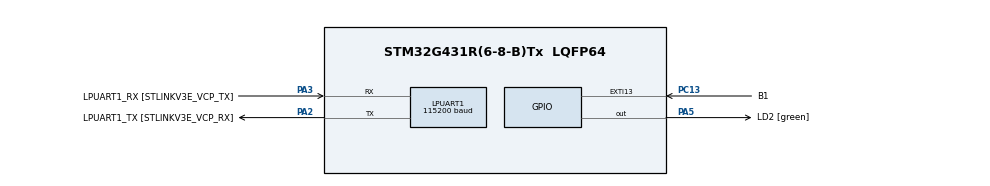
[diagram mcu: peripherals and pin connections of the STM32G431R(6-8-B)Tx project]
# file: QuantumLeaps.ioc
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LPUART1.BaudRate=115200
LPUART1.FIFOMode=UART_FIFOMODE_ENABLE
Mcu.Family=STM32G4
Mcu.Name=STM32G431R(6-8-B)Tx
Mcu.Package=LQFP64
NVIC.EXTI15_10_IRQn=true\:0\:0\:false\:false\:true\:true\:true\:false
NVIC.LPUART1_IRQn=true\:0\:0\:false\:false\:true\:true\:true\:true
NVIC.PriorityGroup=NVIC_PRIORITYGROUP_4
PA13.GPIO_Label=T_SWDIO
PA13.Signal=SYS_JTMS-SWDIO
PA14.GPIO_Label=T_SWCLK
PA14.Signal=SYS_JTCK-SWCLK
PA2.GPIO_Label=LPUART1_TX [STLINKV3E_VCP_RX]
PA2.Mode=Asynchronous
PA2.Signal=LPUART1_TX
PA3.GPIO_Label=LPUART1_RX [STLINKV3E_VCP_TX]
PA3.Mode=Asynchronous
PA3.Signal=LPUART1_RX
PA5.GPIO_Label=LD2 [green]
PA5.Signal=GPIO_Output
PB3.GPIO_Label=T_SWO
PB3.Signal=SYS_JTDO-SWO
PC13.GPIO_Label=B1
PC13.Signal=GPXTI13
PC14-OSC32_IN.GPIO_Label=RCC_OSC32_OUT
PC14-OSC32_IN.Signal=RCC_OSC32_IN
PC15-OSC32_OUT.GPIO_Label=RCC_OSC32_OUT
PC15-OSC32_OUT.Signal=RCC_OSC32_OUT
PF0-OSC_IN.GPIO_Label=RCC_OSC_IN
PF0-OSC_IN.Signal=RCC_OSC_IN
PF1-OSC_OUT.GPIO_Label=RCC_OSC_OUT
PF1-OSC_OUT.Signal=RCC_OSC_OUT
ProjectManager.HeapSize=0x200
ProjectManager.StackSize=0x400
ProjectManager.TargetToolchain=STM32CubeIDE
QuantumLeaps.qpc.7.3.4.qpcCcRTEFJjEventOoProcessor=qep
QuantumLeaps.qpc.7.3.4.qpcCcRTEFJjFramework=qf
QuantumLeaps.qpc.7.3.4.qpcCcRTEFJjRealAaTimeOoKernel=qk
QuantumLeaps.qpc.7.3.4.qpcCcRTEFJjSoftwareOotracing=qs
RCC.ADC12Freq_Value=170000000
RCC.AHBFreq_Value=170000000
RCC.APB1Freq_Value=170000000
RCC.APB1TimFreq_Value=170000000
RCC.APB2Freq_Value=170000000
RCC.APB2TimFreq_Value=170000000
RCC.CortexFreq_Value=170000000
RCC.EXTERNAL_CLOCK_VALUE=12288000
RCC.HCLKFreq_Value=170000000
RCC.HSE_VALUE=24000000
RCC.HSI48_VALUE=48000000
RCC.HSI_VALUE=16000000
RCC.LSE_VALUE=32768
RCC.PLLM=RCC_PLLM_DIV4
RCC.PLLN=85
RCC.RTCClockSelection=RCC_RTCCLKSOURCE_LSE
RCC.SYSCLKFreq_VALUE=170000000
RCC.SYSCLKSource=RCC_SYSCLKSOURCE_PLLCLK
RCC.USBFreq_Value=170000000
RCC.VCOOutputFreq_Value=340000000
VP_QuantumLeaps.qpc_VS_RTEFJjqpc_7.3.4_7.3.4.Mode=RTEFJjqpc
VP_SYS_VS_DBSignals.Mode=DisableDeadBatterySignals
board=NUCLEO-G431RB

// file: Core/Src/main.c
/* USER CODE BEGIN Header */
/**
  ******************************************************************************
  * @file           : main.c
  * @brief          : Main program body
  ******************************************************************************
  * @attention
  *
  * Copyright (c) 2024 STMicroelectronics.
  * All rights reserved.
  *
  * This software is licensed under terms that can be found in the LICENSE file
  * in the root directory of this software component.
  * If no LICENSE file comes with this software, it is provided AS-IS.
  *
  ******************************************************************************
  */
/* USER CODE END Header */
#include "main.h"

/* USER CODE BEGIN Includes */
#include "qpc.h"
#include <stdio.h>
/* USER CODE END Includes */

void SystemClock_Config(void);
static void MX_GPIO_Init(void);
static void MX_LPUART1_UART_Init(void);

int main(void)
{

  /* MCU Configuration--------------------------------------------------------*/

  /* Reset of all peripherals, Initializes the Flash interface and the Systick. */
  HAL_Init();

  /* Configure the system clock */
  SystemClock_Config();

  /* Initialize all configured peripherals */
  MX_GPIO_Init();
  MX_LPUART1_UART_Init();
  /* USER CODE BEGIN 2 */

  //char msg[200];
  //sprintf(msg, "Blinky example with interrupts\r\n");
  //HAL_UART_Transmit(&hlpuart1, (uint8_t *)msg, strlen(msg), 2000);

  QF_init();       	// Initialize the framework and the underlying RT kernel
  BSP_init();      	// Initialize the BSP
  BSP_start();     	// Start the AOs/Threads

  return QF_run(); 			// run the QF application (endless loop)

  /* USER CODE END 2 */

  /* Infinite loop */
  /* USER CODE BEGIN WHILE */
  //while( 1 ){

    /* USER CODE END WHILE */

    /* USER CODE BEGIN 3 */
  //}
  /* USER CODE END 3 */
}

void SystemClock_Config(void)
{
  LL_FLASH_SetLatency(LL_FLASH_LATENCY_4);
  while(LL_FLASH_GetLatency() != LL_FLASH_LATENCY_4)
  {
  }
  LL_PWR_EnableRange1BoostMode();
  LL_RCC_HSI_Enable();
   /* Wait till HSI is ready */
  while(LL_RCC_HSI_IsReady() != 1)
  {
  }

  LL_RCC_HSI_SetCalibTrimming(64);
  LL_RCC_PLL_ConfigDomain_SYS(LL_RCC_PLLSOURCE_HSI, LL_RCC_PLLM_DIV_4, 85, LL_RCC_PLLR_DIV_2);
  LL_RCC_PLL_EnableDomain_SYS();
  LL_RCC_PLL_Enable();
   /* Wait till PLL is ready */
  while(LL_RCC_PLL_IsReady() != 1)
  {
  }

  LL_RCC_SetSysClkSource(LL_RCC_SYS_CLKSOURCE_PLL);
  LL_RCC_SetAHBPrescaler(LL_RCC_SYSCLK_DIV_2);
   /* Wait till System clock is ready */
  while(LL_RCC_GetSysClkSource() != LL_RCC_SYS_CLKSOURCE_STATUS_PLL)
  {
  }

  /* Insure 1us transition state at intermediate medium speed clock*/
  for (__IO uint32_t i = (170 >> 1); i !=0; i--);

  /* Set AHB prescaler*/
  LL_RCC_SetAHBPrescaler(LL_RCC_SYSCLK_DIV_1);
  LL_RCC_SetAPB1Prescaler(LL_RCC_APB1_DIV_1);
  LL_RCC_SetAPB2Prescaler(LL_RCC_APB2_DIV_1);
  LL_SetSystemCoreClock(170000000);

   /* Update the time base */
  if (HAL_InitTick (TICK_INT_PRIORITY) != HAL_OK)
  {
    Error_Handler();
  }
}

static void MX_LPUART1_UART_Init(void)
{

  LL_LPUART_InitTypeDef LPUART_InitStruct = {0};

  LL_GPIO_InitTypeDef GPIO_InitStruct = {0};

  LL_RCC_SetLPUARTClockSource(LL_RCC_LPUART1_CLKSOURCE_PCLK1);

  /* Peripheral clock enable */
  LL_APB1_GRP2_EnableClock(LL_APB1_GRP2_PERIPH_LPUART1);

  LL_AHB2_GRP1_EnableClock(LL_AHB2_GRP1_PERIPH_GPIOA);
  /**LPUART1 GPIO Configuration
  PA2   ------> LPUART1_TX
  PA3   ------> LPUART1_RX
  */
  GPIO_InitStruct.Pin = LL_GPIO_PIN_2;
  GPIO_InitStruct.Mode = LL_GPIO_MODE_ALTERNATE;
  GPIO_InitStruct.Speed = LL_GPIO_SPEED_FREQ_LOW;
  GPIO_InitStruct.OutputType = LL_GPIO_OUTPUT_PUSHPULL;
  GPIO_InitStruct.Pull = LL_GPIO_PULL_NO;
  GPIO_InitStruct.Alternate = LL_GPIO_AF_12;
  LL_GPIO_Init(GPIOA, &GPIO_InitStruct);

  GPIO_InitStruct.Pin = LL_GPIO_PIN_3;
  GPIO_InitStruct.Mode = LL_GPIO_MODE_ALTERNATE;
  GPIO_InitStruct.Speed = LL_GPIO_SPEED_FREQ_LOW;
  GPIO_InitStruct.OutputType = LL_GPIO_OUTPUT_PUSHPULL;
  GPIO_InitStruct.Pull = LL_GPIO_PULL_NO;
  GPIO_InitStruct.Alternate = LL_GPIO_AF_12;
  LL_GPIO_Init(GPIOA, &GPIO_InitStruct);

  /* LPUART1 interrupt Init */
  NVIC_SetPriority(LPUART1_IRQn, NVIC_EncodePriority(NVIC_GetPriorityGrouping(),0, 0));
  NVIC_EnableIRQ(LPUART1_IRQn);

  LPUART_InitStruct.PrescalerValue = LL_LPUART_PRESCALER_DIV1;
  LPUART_InitStruct.BaudRate = 115200;
  LPUART_InitStruct.DataWidth = LL_LPUART_DATAWIDTH_8B;
  LPUART_InitStruct.StopBits = LL_LPUART_STOPBITS_1;
  LPUART_InitStruct.Parity = LL_LPUART_PARITY_NONE;
  LPUART_InitStruct.TransferDirection = LL_LPUART_DIRECTION_TX_RX;
  LPUART_InitStruct.HardwareFlowControl = LL_LPUART_HWCONTROL_NONE;
  LL_LPUART_Init(LPUART1, &LPUART_InitStruct);
  LL_LPUART_SetTXFIFOThreshold(LPUART1, LL_LPUART_FIFOTHRESHOLD_1_8);
  LL_LPUART_SetRXFIFOThreshold(LPUART1, LL_LPUART_FIFOTHRESHOLD_1_8);
  LL_LPUART_EnableFIFO(LPUART1);

  LL_LPUART_Enable(LPUART1);

  /* Polling LPUART1 initialisation */
  while((!(LL_LPUART_IsActiveFlag_TEACK(LPUART1))) || (!(LL_LPUART_IsActiveFlag_REACK(LPUART1))))
  {
  }

}

static void MX_GPIO_Init(void)
{
  GPIO_InitTypeDef GPIO_InitStruct = {0};

  /* GPIO Ports Clock Enable */
  __HAL_RCC_GPIOC_CLK_ENABLE();
  __HAL_RCC_GPIOF_CLK_ENABLE();
  __HAL_RCC_GPIOA_CLK_ENABLE();
  __HAL_RCC_GPIOB_CLK_ENABLE();

  /*Configure GPIO pin Output Level */
  HAL_GPIO_WritePin(LD2_GPIO_Port, LD2_Pin, GPIO_PIN_RESET);

  /*Configure GPIO pin : B1_Pin */
  GPIO_InitStruct.Pin = B1_Pin;
  GPIO_InitStruct.Mode = GPIO_MODE_IT_RISING;
  GPIO_InitStruct.Pull = GPIO_NOPULL;
  HAL_GPIO_Init(B1_GPIO_Port, &GPIO_InitStruct);

  /*Configure GPIO pin : LD2_Pin */
  GPIO_InitStruct.Pin = LD2_Pin;
  GPIO_InitStruct.Mode = GPIO_MODE_OUTPUT_PP;
  GPIO_InitStruct.Pull = GPIO_NOPULL;
  GPIO_InitStruct.Speed = GPIO_SPEED_FREQ_LOW;
  HAL_GPIO_Init(LD2_GPIO_Port, &GPIO_InitStruct);

  /* EXTI interrupt init*/
  HAL_NVIC_SetPriority(EXTI15_10_IRQn, 0, 0);

}

/* USER CODE BEGIN 4 */
/*
void HAL_GPIO_EXTI_Callback(uint16_t GPIO_Pin){
	if( GPIO_Pin == GPIO_PIN_13 ){ /// nFault
		//static QEvt const buttonEvt = { START_SIG, 0U, 0U};
		//QF_PUBLISH(&buttonEvt, 0U);
	}
}*/

/* USER CODE END 4 */

void Error_Handler(void)
{
  __disable_irq();
  while (1)
  {
  }
}
